# H6 register map
Vendor: Allwinner; Series: H6; File version: 0.1
CPU: CA53 0, little endian, MPU, no FPU, 0 interrupt priority bits
Registers are 32-bit, read-write, reset 0x0 unless marked. A register's access mark holds for its fields unless they carry their own. Offsets are from the block's base; [hi:lo] are bit positions; lines under a group give offsets from that group; {n}, {i} and the like mark numbered series; 'fields as' and 'values as' point back to an identical list.

## TCON_TV0
Base 0x06515000
0x00 TV_GCTL_REG — TV Global Control Register
  [31] TV_EN — 0: disable 1: enable When it`s disabled, the module will be reset to idle state.
    0=disable; 1=enable When it`s disabled, the module will be reset to idle state
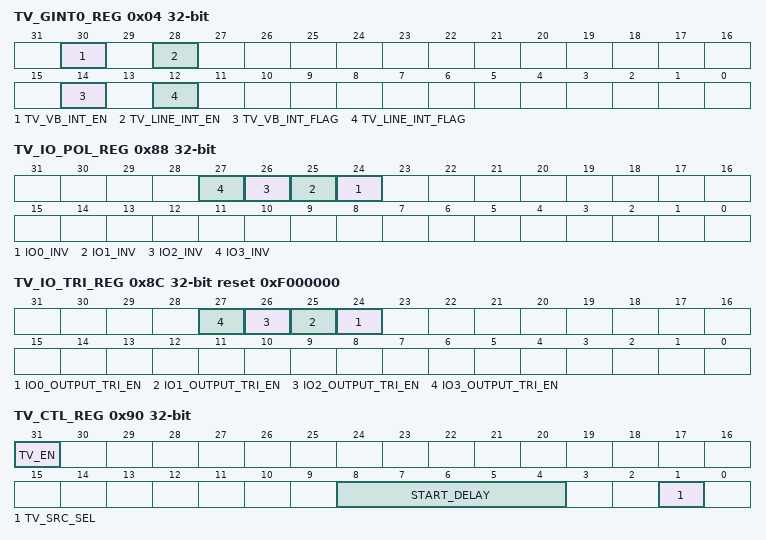
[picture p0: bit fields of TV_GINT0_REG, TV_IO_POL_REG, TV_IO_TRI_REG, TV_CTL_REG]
0x04 TV_GINT0_REG — TV Global Interrupt Register0
  [30] TV_VB_INT_EN — 0: disable 1: enable
    0=disable; 1=enable
  [28] TV_LINE_INT_EN — 0: disable 1: enable
    0=disable; 1=enable
  [14] TV_VB_INT_FLAG — Asserted during vertical no-display period every frame. Write 0 to clear it.
  [12] TV_LINE_INT_FLAG — trigger when SY1 match the current TV scan line Write 0 to clear it.
0x08 TV_GINT1_REG — TV Global Interrupt Register1
  [11:0] TV_LINE_INT_NUM — scan line for TV line trigger(including inactive lines) Setting it for the specified line for trigger 1. SY1 is writable only when LINE_TRG1 disable.
0x40 TV0_CTL_REG
  [2:0] TV_SRC_SEL — 000: DE 001: Color Check 010: Grayscale Check 011: Black by White Check 100: Reserved 101: Reserved 111: Gridding Check
    0=DE; 1=Color Check; 2=Grayscale Check; 3=Black by White Check; 7=Gridding Check
0x88 TV_IO_POL_REG — TV SYNC Signal Polarity Register
  [all] fields
    0=not_invert; 1=invert
  [n+24] IO{n}_INV (n=0..3) — 0: not invert 1: invert
0x8C TV_IO_TRI_REG reset 0xF000000 — TV ISYNC Signal IO Control Register
  [all] fields
    1=disable; 0=enable
  [n+24] IO{n}_OUTPUT_TRI_EN (n=0..3) — 1: disable 0: enable
0x90 TV_CTL_REG — TV Control Register
  [31] TV_EN — 0: disable 1: enable
    0=disable; 1=enable
  [8:4] START_DELAY — This is for DE0 and DE1
  [1] TV_SRC_SEL — 0: reserved 1: BLUE data The priority of this bit is higher than TV_SRC_SEL(bit[2:0]) in TV_SRC_CTL_REG.
    1=BLUE data The priority of this bit is higher than TV_SRC_SEL(bit[2:0]) in TV_SRC_CTL_REG
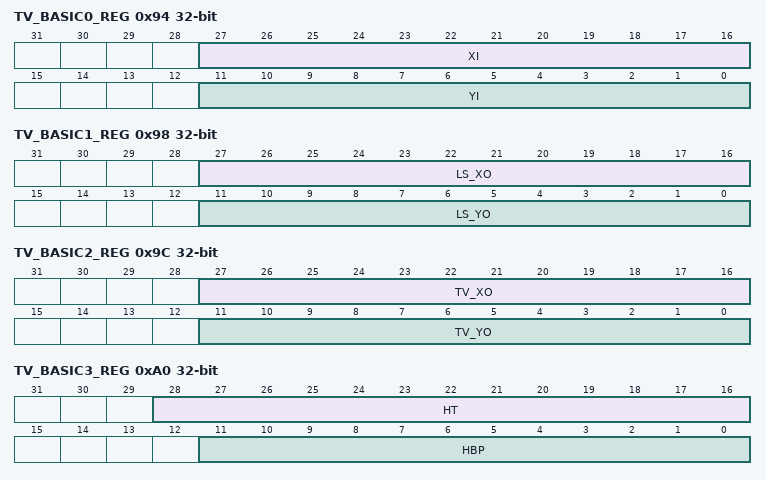
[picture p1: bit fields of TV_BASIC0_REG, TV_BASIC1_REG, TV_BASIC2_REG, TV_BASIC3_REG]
0x94 TV_BASIC0_REG — TV Basic Timing Register0
  [27:16] XI — source width is X+1
  [11:0] YI — source height is Y+1
0x98 TV_BASIC1_REG — TV Basic Timing Register1
  [27:16] LS_XO — width is LS_XO+1
  [11:0] LS_YO — width is LS_YO+1 this version LS_YO = TV_YI
0x9C TV_BASIC2_REG — TV Basic Timing Register2
  [27:16] TV_XO — width is TV_XO+1
  [11:0] TV_YO — height is TV_YO+1
0xA0 TV_BASIC3_REG — TV Basic Timing Register3
  [28:16] HT — horizontal total time Thcycle = (HT+1) * Thdclk
  [11:0] HBP — horizontal back porch Thbp = (HBP +1) * Thdclk
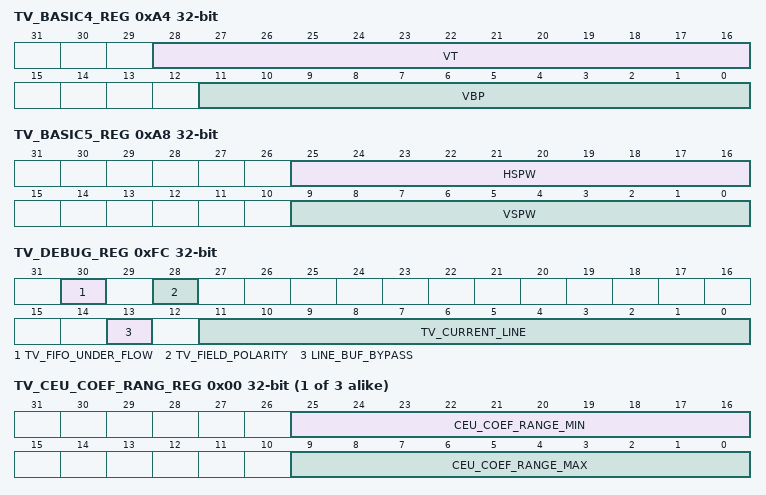
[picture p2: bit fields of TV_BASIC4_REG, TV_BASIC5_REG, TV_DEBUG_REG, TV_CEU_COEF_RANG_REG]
0xA4 TV_BASIC4_REG — TV Basic Timing Register4
  [28:16] VT — horizontal total time (in HD line) Tvt = VT/2 * Th
  [11:0] VBP — horizontal back porch (in HD line) Tvbp = (VBP +1) * Th
0xA8 TV_BASIC5_REG — TV Basic Timing Register5
  [25:16] HSPW — horizontal Sync Pulse Width (in dclk) Thspw = (HSPW+1) * Tdclk HT> (HSPW+1)
  [9:0] VSPW — vertical Sync Pulse Width (in lines) Tvspw = (VSPW+1) * Th VT/2 > (VSPW+1)
0xFC TV_DEBUG_REG — TV Debug Register
  [30] TV_FIFO_UNDER_FLOW
  [28] TV_FIELD_POLARITY ro — 0: second field 1: first field
    0=second; 1=first
  [13] LINE_BUF_BYPASS — 0: used 1: bypass
    0=used; 1=bypass
  [11:0] TV_CURRENT_LINE ro
0x100 TV_CEU_CTL_REG — TV CEU Control Register
  [31] CEU_EN — 0: bypass 1: enable
    0=bypass; 1=enable
{0x110+4i} TV_CEU_COEF_MUL_REG_{i} (i=0..2) — TV CEU Coefficient Register0(N=0,1,2,4,5,6,8,9,10)
  [8] CEU_COEF_MUL_VALUE — 1. CEU_Coef_Mul_Value only can be 0 or 1 2. REG Map: N=0: Rr N=1: Rg N=2: Rb N=4: Gr N=5: Gg N=6: Gb N=8: Br N=9: Bg N=10: Bb
{0x110+4i} TV_CEU_COEF_MUL_REG_{i} (i=4..6) — TV CEU Coefficient Register0(N=0,1,2,4,5,6,8,9,10)
  fields as TV_CEU_COEF_MUL_REG_0
{0x110+4i} TV_CEU_COEF_MUL_REG_{i} (i=8..10) — TV CEU Coefficient Register0(N=0,1,2,4,5,6,8,9,10)
  fields as TV_CEU_COEF_MUL_REG_0
{0x140+4i} _N[{i}] (i=0..2) group
  0x00 TV_CEU_COEF_RANG_REG — TV CEU Coefficient Register2(N=0,1,2)
    [25:16] CEU_COEF_RANGE_MIN — unsigned 10bit value, range of [0,1023]
    [9:0] CEU_COEF_RANGE_MAX — unsigned 10bit value, range of [0,1023]
  0x1C4 TV_FILL_BEGIN_REG — TV Fill Data Begin Register(N=0,1,2)
    [23:0] FILL_BEGIN
  0x1C8 TV_FILL_END_REG — TV Fill Data End Register(N=0,1,2)
    [23:0] FILL_END
  0x1CC TV_FILL_DATA_REG
    [29:0] FILL_VALUE
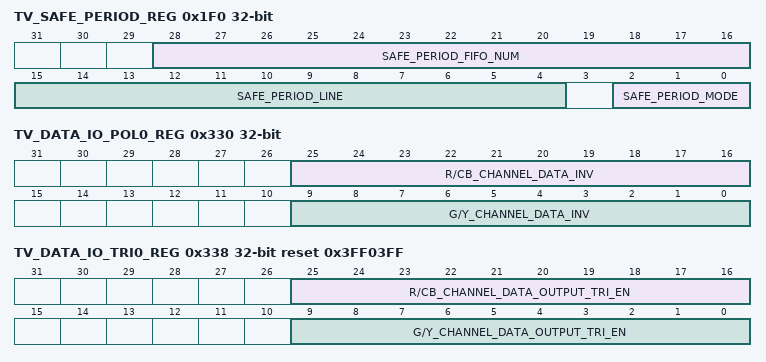
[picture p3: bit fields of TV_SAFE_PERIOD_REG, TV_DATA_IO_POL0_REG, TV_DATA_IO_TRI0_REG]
0x1F0 TV_SAFE_PERIOD_REG — TV Safe Period Register
  [28:16] SAFE_PERIOD_FIFO_NUM
  [15:4] SAFE_PERIOD_LINE
  [2:0] SAFE_PERIOD_MODE — 000: unsafe 001: safe 010: safe at line_buf_curr_num > safe_period_fifo_num 011: safe at 2 and safe at sync active 100: safe at line
0x300 TV_FILL_CTL_REG — TV Fill Data Control Register
  [31] TV_FILL_EN — 0: bypass 1: enable
    0=bypass; 1=enable
0x330 TV_DATA_IO_POL0_REG — TCON Data IO Polarity Control 0
  [25:16] R/CB_CHANNEL_DATA_INV — 0: normal polarity 1: invert the specify output
  [9:0] G/Y_CHANNEL_DATA_INV — 0: normal polarity 1: invert the specify output
0x334 TV_DATA_IO_POL1_REG — TCON Data IO Polarity Control 1
  [25:16] B/CR_CHANNEL_DATA_INV — 0: normal polarity 1: invert the specify output
0x338 TV_DATA_IO_TRI0_REG reset 0x3FF03FF
  [25:16] R/CB_CHANNEL_DATA_OUTPUT_TRI_EN — 1: disable 0: enable Only high 6-bit is valid.
  [9:0] G/Y_CHANNEL_DATA_OUTPUT_TRI_EN — 1: disable 0: enable Only high 6-bit is valid.
0x33C TV_DATA_IO_TRI1_REG reset 0x3FF0000
  [25:16] B/CR_CHANNEL_DATA_OUTPUT_TRI_EN — 1: disable 0: enable Only high 6-bit is valid.
0x340 TV_PIXELDEPTH_MODE_REG — TV Pixeldepth Mode Control Register
  [0] COLORBAR — Colorbar Pixeldepth mode(Only valid for Colorbar output) 0: 8-bit mode 1: 10-bit mode
    0=_8_bit_mode; 1=_10_bit_mode
